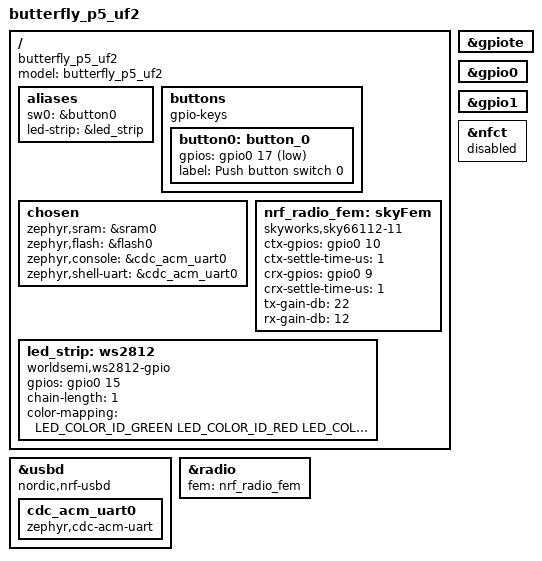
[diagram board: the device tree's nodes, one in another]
// Copyright (c) 2024 Nordic Semiconductor ASA
// SPDX-License-Identifier: Apache-2.0

/dts-v1/;
#include <nordic/nrf52833_qiaa.dtsi>
#include <dt-bindings/led/led.h>

/ {
	model = "butterfly_p5_uf2";
	compatible = "butterfly_p5_uf2";

	aliases {
		sw0 = &button0;
		led-strip = &led_strip;
	};

	buttons {
		compatible = "gpio-keys";
		button0: button_0 {
			gpios = <&gpio0 17 (GPIO_PULL_UP | GPIO_ACTIVE_LOW)>;
			label = "Push button switch 0";
		};
	};

	chosen {
		zephyr,sram = &sram0;
		zephyr,flash = &flash0;
		zephyr,console = &cdc_acm_uart0;
		zephyr,shell-uart = &cdc_acm_uart0;
	};

	nrf_radio_fem: skyFem { // ripped straight from holyiot dts, but it works
        compatible = "skyworks,sky66112-11", "generic-fem-two-ctrl-pins";
        ctx-gpios = <&gpio0 10 GPIO_ACTIVE_HIGH>;
        ctx-settle-time-us = <1>;
        crx-gpios = <&gpio0 9 GPIO_ACTIVE_HIGH>;
        crx-settle-time-us = <1>;
        tx-gain-db = <22>;
		rx-gain-db = <12>;
    };

	led_strip: ws2812 { 
        compatible = "worldsemi,ws2812-gpio";
        gpios = <&gpio0 15 GPIO_ACTIVE_HIGH>;
        chain-length = <1>;
        color-mapping = <LED_COLOR_ID_GREEN
                 LED_COLOR_ID_RED
                 LED_COLOR_ID_BLUE>;
    };

};

&gpiote {
	status = "okay";
};

&gpio0 {
	status = "okay";
};

&gpio1 {
	status = "okay";
};

zephyr_udc0: &usbd {
	compatible = "nordic,nrf-usbd";
	status = "okay";
	cdc_acm_uart0: cdc_acm_uart0 {
		compatible = "zephyr,cdc-acm-uart";
	};
};

&nfct {
	status = "disabled";
};

&radio {
	fem = <&nrf_radio_fem>;
};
